# APM32F103xx register map
File version: 1.0
CPU: CM3 r2p1, little endian, no MPU, no FPU, 4 interrupt priority bits
Registers are 32-bit, read-write, reset 0x0 unless marked. A register's access mark holds for its fields unless they carry their own. Offsets are from the block's base; [hi:lo] are bit positions; {n}, {i} and the like mark numbered series; 'fields as' and 'values as' point back to an identical list.

## EMMC
Base 0xA0000000
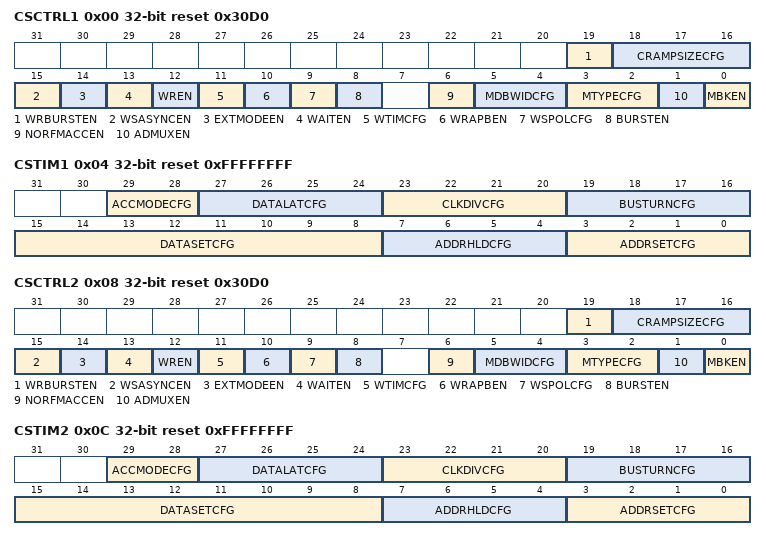
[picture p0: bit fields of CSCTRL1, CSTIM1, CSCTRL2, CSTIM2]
0x00 CSCTRL1 reset 0x30D0 — SRAM/NOR-Flash chip-select control register 1
  [19] WRBURSTEN, [18:16] CRAMPSIZECFG, [15] WSASYNCEN, [14] EXTMODEEN, [13] WAITEN, [12] WREN, [11] WTIMCFG, [10] WRAPBEN, [9] WSPOLCFG, [8] BURSTEN, [6] NORFMACCEN, [5:4] MDBWIDCFG, [3:2] MTYPECFG, [1] ADMUXEN, [0] MBKEN
0x04 CSTIM1 reset 0xFFFFFFFF — SRAM/NOR-Flash chip-select timing register 1
  [29:28] ACCMODECFG, [27:24] DATALATCFG, [23:20] CLKDIVCFG, [19:16] BUSTURNCFG, [15:8] DATASETCFG, [7:4] ADDRHLDCFG, [3:0] ADDRSETCFG
0x08 CSCTRL2 reset 0x30D0 — SRAM/NOR-Flash chip-select control register 2
  fields as CSCTRL1
0x0C CSTIM2 reset 0xFFFFFFFF — SRAM/NOR-Flash chip-select timing register 2
  fields as CSTIM1
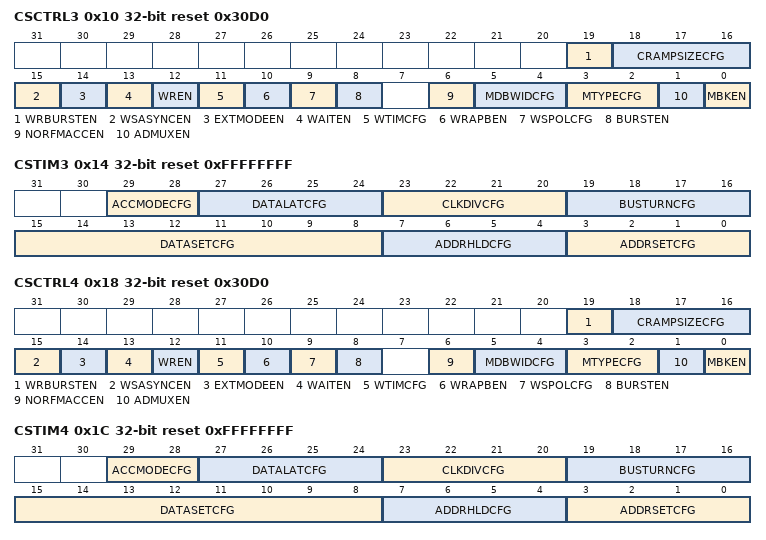
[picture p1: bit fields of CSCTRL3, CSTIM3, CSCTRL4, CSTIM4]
0x10 CSCTRL3 reset 0x30D0 — SRAM/NOR-Flash chip-select control register 3
  fields as CSCTRL1
0x14 CSTIM3 reset 0xFFFFFFFF — SRAM/NOR-Flash chip-select timing register 3
  fields as CSTIM1
0x18 CSCTRL4 reset 0x30D0 — SRAM/NOR-Flash chip-select control register 4
  fields as CSCTRL1
0x1C CSTIM4 reset 0xFFFFFFFF — SRAM/NOR-Flash chip-select timing register 4
  fields as CSTIM1
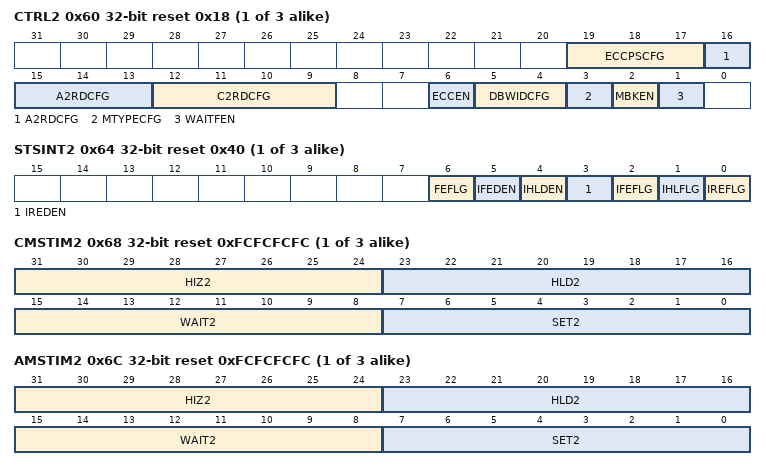
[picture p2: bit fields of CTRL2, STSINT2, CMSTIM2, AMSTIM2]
{0x20+0x20*i} CTRL{i} reset 0x18 (i=2..4) — PC Card/NAND Flash control register {i}
  [19:17] ECCPSCFG
  [16:13] A2RDCFG
  [12:9] C2RDCFG — C2RDCF
  [6] ECCEN
  [5:4] DBWIDCFG
  [3] MTYPECFG
  [2] MBKEN
  [1] WAITFEN
{0x24+0x20*i} STSINT{i} access per field reset 0x40 (i=2..4) — FIFO status and interrupt register {i}
  [6] FEFLG ro, [5] IFEDEN rw, [4] IHLDEN rw, [3] IREDEN rw, [2] IFEFLG rw, [1] IHLFLG rw, [0] IREFLG rw
{0x28+0x20*i} CMSTIM{i} reset 0xFCFCFCFC (i=2..4) — Common memory space timing register {i}
  [31:24] HIZ{i} — Common memory {i} databus HiZ time
  [23:16] HLD{i} — Common memory {i} hold time
  [15:8] WAIT{i} — Common memory {i} wait time
  [7:0] SET{i} — Common memory {i} setup time
{0x2C+0x20*i} AMSTIM{i} reset 0xFCFCFCFC (i=2..4) — Attribute memory space timing register {i}
  [31:24] HIZ{i} — Attribute memory {i} databus HiZ time
  [23:16] HLD{i} — Attribute memory {i} hold time
  [15:8] WAIT{i} — Attribute memory {i} wait time
  [7:0] SET{i} — Attribute memory {i} setup time
0x74 ECCRS2 ro — ECC result register 2
  [31:0] ECCRS2 — ECC result 2
0x94 ECCRS3 ro — ECC result register 3
  [31:0] ECCRS3 — ECC result 3
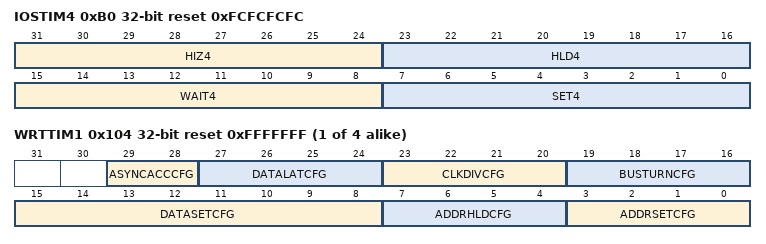
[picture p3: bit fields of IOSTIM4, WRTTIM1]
0xB0 IOSTIM4 reset 0xFCFCFCFC — I/O space timing register 4
  [31:24] HIZ4, [23:16] HLD4, [15:8] WAIT4, [7:0] SET4
{0xFC+8i} WRTTIM{i} reset 0xFFFFFFF (i=1..4) — SRAM/NOR-Flash write timing registers {i}
  [29:28] ASYNCACCCFG, [27:24] DATALATCFG, [23:20] CLKDIVCFG, [19:16] BUSTURNCFG, [15:8] DATASETCFG, [7:4] ADDRHLDCFG, [3:0] ADDRSETCFG

## DMC — Dynamic memory controler
Base 0xA0000000; alternate view of EMMC
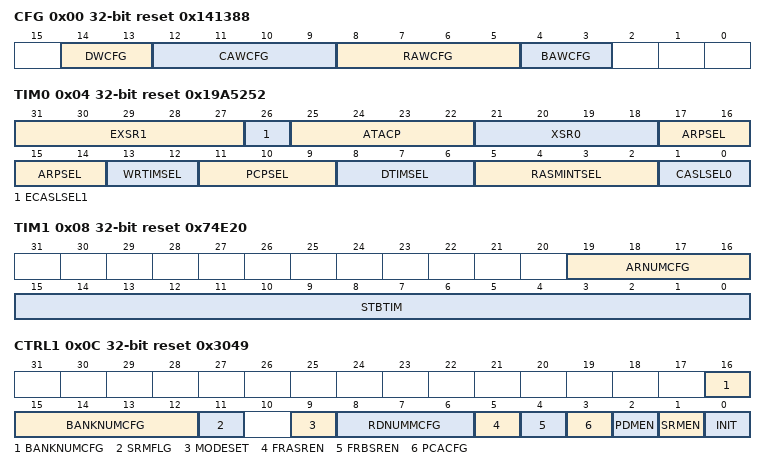
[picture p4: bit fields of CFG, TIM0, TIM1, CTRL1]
0x00 CFG reset 0x141388 — Configuraion register
  [14:13] DWCFG, [12:9] CAWCFG, [8:5] RAWCFG, [4:3] BAWCFG
0x04 TIM0 reset 0x19A5252 — Timing register 0
  [31:27] EXSR1, [26] ECASLSEL1, [25:22] ATACP, [21:18] XSR0, [17:14] ARPSEL, [13:12] WRTIMSEL, [11:9] PCPSEL, [8:6] DTIMSEL, [5:2] RASMINTSEL, [1:0] CASLSEL0
0x08 TIM1 reset 0x74E20 — Timing register 1
  [19:16] ARNUMCFG, [15:0] STBTIM
0x0C CTRL1 access per field reset 0x3049 — Control register 1
  [16:12] BANKNUMCFG rw
  [11] SRMFLG ro
  [9] MODESET rw
  [8:6] RDNUMMCFG rw — RDNUMCFG
  [5] FRASREN rw
  [4] FRBSREN rw
  [3] PCACFG rw
  [2] PDMEN rw
  [1] SRMEN rw
  [0] INIT rw
0x10 REF reset 0xC3 — refresh register
  [15:0] RCYCCFG
0x14 CHIPSEL — Chip select register
  [31:16] BACHIPSEL
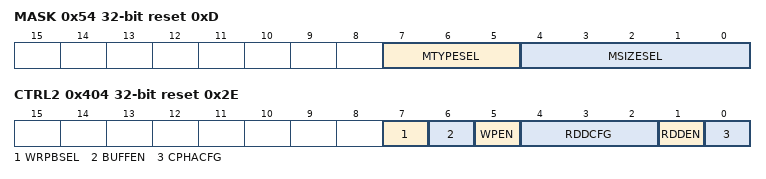
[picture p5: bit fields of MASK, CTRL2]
0x54 MASK reset 0xD
  [7:5] MTYPESEL, [4:0] MSIZESEL
0x400 SW — switch register
  [0] MCSW — Memory Controller Function Switch
0x404 CTRL2 reset 0x2E — Control register 2
  [7] WRPBSEL, [6] BUFFEN, [5] WPEN, [4:2] RDDCFG, [1] RDDEN, [0] CPHACFG

## QSPI — Serial peripheral interface
Base 0xA0000000; alternate view of EMMC
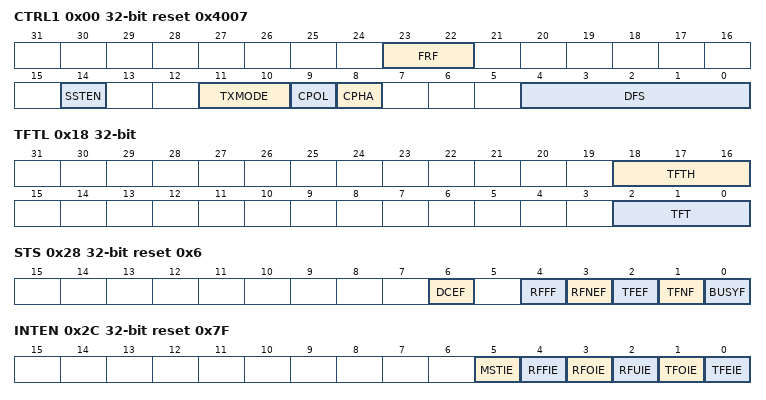
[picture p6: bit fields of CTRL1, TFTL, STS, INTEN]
0x00 CTRL1 reset 0x4007 — Control register 1
  [23:22] FRF, [14] SSTEN, [11:10] TXMODE, [9] CPOL, [8] CPHA, [4:0] DFS
0x04 CTRL2 — Control register 2
  [15:0] NDF
0x08 SSIEN — QSPI Enable register
  [0] EN
0x10 SLAEN — QSPI Slave enable register
  [0] SLAEN
0x14 BR — Baudrate register
  [15:0] CLKDIV
0x18 TFTL — Transmission FIFO threshhold level register
  [18:16] TFTH, [2:0] TFT
0x1C RFTL — Reception FIFO threshhold level register
  [2:0] RFT
0x20 TFL — Transmission FIFO level register
  [2:0] TFL
0x24 RFL — Reception FIFO level register
  [2:0] RFL
0x28 STS reset 0x6 — Status register
  [6] DCEF, [4] RFFF, [3] RFNEF, [2] TFEF, [1] TFNF, [0] BUSYF
0x2C INTEN reset 0x7F — Interrupt enable register
  [5] MSTIE, [4] RFFIE, [3] RFOIE, [2] RFUIE, [1] TFOIE, [0] TFEIE
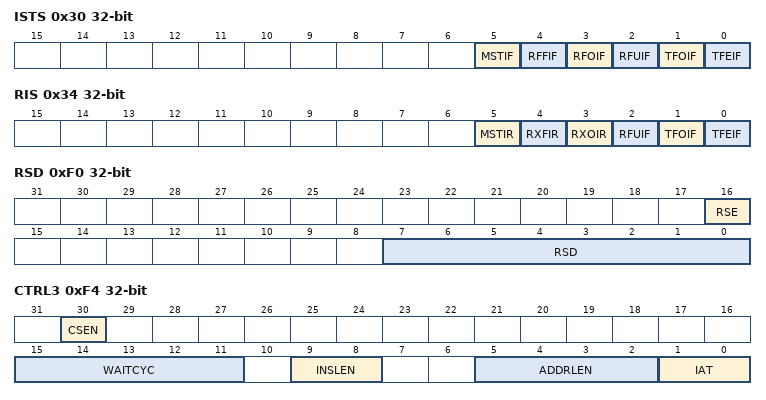
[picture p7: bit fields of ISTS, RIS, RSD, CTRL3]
0x30 ISTS ro — Interrupt status register
  [5] MSTIF, [4] RFFIF, [3] RFOIF, [2] RFUIF, [1] TFOIF, [0] TFEIF
0x34 RIS ro — Raw interrupt register
  [5] MSTIR, [4] RXFIR, [3] RXOIR, [2] RFUIF, [1] TFOIF, [0] TFEIF
0x38 TFOIC ro — Transmission FIFO overflow interrupt clear register
  [0] TFOIC
0x3C RFOIC ro — Reception FIFO overflow interrupt clear register
  [0] RFOIC
0x40 RFUIC ro — Reception FIFO underflow interrupt clear register
  [0] RFUIC
0x44 MIC ro — Master interrupt clear register
  [0] MIC
0x48 ICF ro — Interrupt clear register
  [0] ICF
0x60 DATA
0xF0 RSD — Reception sample register
  [16] RSE, [7:0] RSD
0xF4 CTRL3 — Control register 3
  [30] CSEN, [15:11] WAITCYC, [9:8] INSLEN, [5:2] ADDRLEN, [1:0] IAT
0x200 IOSW — IO switch register
  [0] IOSW — I/O switch

## USBD — Universal serial bus full-speed device interface
Base 0x40005C00
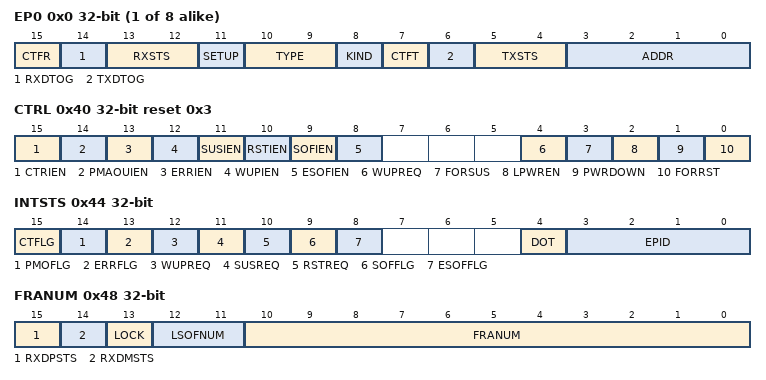
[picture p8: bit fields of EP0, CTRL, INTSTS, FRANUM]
{0x0+4i} EP{i} (i=0..7) — endpoint {i} register
  [15] CTFR — Correct transfer for reception
  [14] RXDTOG — Data Toggle, for reception transfers
  [13:12] RXSTS — Status bits, for reception transfers
  [11] SETUP — Setup transaction completed
  [10:9] TYPE — Endpoint type
  [8] KIND — Endpoint kind
  [7] CTFT — Correct Transfer for transmission
  [6] TXDTOG — Data Toggle, for transmission transfers
  [5:4] TXSTS — Status bits, for transmission transfers
  [3:0] ADDR — Endpoint address
0x40 CTRL reset 0x3 — control register
  [15] CTRIEN — Correct transfer interrupt mask
  [14] PMAOUIEN — Packet memory area over / underrun interrupt mask
  [13] ERRIEN — Error interrupt mask
  [12] WUPIEN — Wakeup interrupt mask
  [11] SUSIEN — Suspend mode interrupt mask
  [10] RSTIEN — USB reset interrupt mask
  [9] SOFIEN — Start of frame interrupt mask
  [8] ESOFIEN — Expected start of frame interrupt mask
  [4] WUPREQ — Wakeup request
  [3] FORSUS — Force suspend
  [2] LPWREN — Low-power mode
  [1] PWRDOWN — Power down
  [0] FORRST — Force USB Reset
0x44 INTSTS — interrupt status register
  [15] CTFLG — Correct transfer
  [14] PMOFLG — Packet memory area over / underrun
  [13] ERRFLG — Error
  [12] WUPREQ — Wakeup
  [11] SUSREQ — Suspend mode request
  [10] RSTREQ — reset request
  [9] SOFFLG — start of frame
  [8] ESOFFLG — Expected start frame
  [4] DOT — Direction of transaction
  [3:0] EPID — Endpoint Identifier
0x48 FRANUM ro — frame number register
  [15] RXDPSTS — Receive data + line status
  [14] RXDMSTS — Receive data - line status
  [13] LOCK — Locked
  [12:11] LSOFNUM — Lost SOF
  [10:0] FRANUM — Frame number
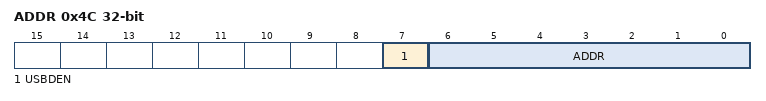
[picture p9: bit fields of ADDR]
0x4C ADDR — device address
  [7] USBDEN — Enable function
  [6:0] ADDR — Device address
0x50 BUFFTB — Buffer table address
  [15:3] BUFFTB — Buffer table
0x100 SWITCH
  [0] SWITCH
